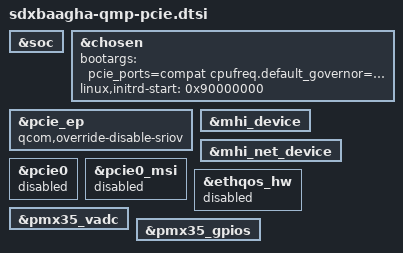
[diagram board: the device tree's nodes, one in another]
// SPDX-License-Identifier: BSD-3-Clause
/*
 * Copyright (c) Qualcomm Technologies, Inc. and/or its subsidiaries.
 */

&soc {
};

&chosen {
	bootargs = "pcie_ports=compat cpufreq.default_governor=performance reboot=w";
	linux,initrd-start = <0x90000000>;
};

&pcie_ep {
	qcom,override-disable-sriov;
	status = "ok";
};

&mhi_device {
	status = "ok";
};

&mhi_net_device {
	status = "ok";
};

&pcie0 {
	status = "disabled";
};

&pcie0_msi {
	status = "disabled";
};

&ethqos_hw {
	status = "disabled";
};

&pmx35_vadc {
	/delete-property/ pinctrl-0;
	/delete-property/ pinctrl-names;
	/delete-node/ pmx35_batt_id;
};

&pmx35_gpios {
	/delete-node/ batt_id;
};
